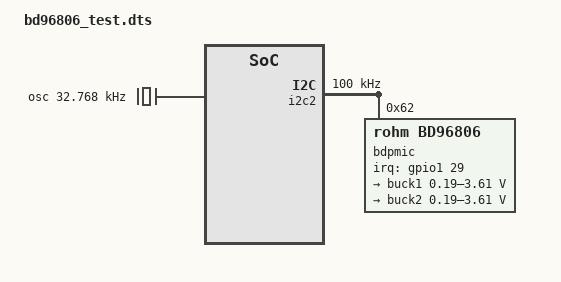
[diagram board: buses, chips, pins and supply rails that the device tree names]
/dts-v1/;
/plugin/;

/{ /* this is our device tree overlay root node */

	compatible = "ti,beaglebone", "ti,beaglebone-black";
	part-number = "BBB-I2C1"; // you can choose any name here but it should be memorable
 	version = "00A0";

/*
	fragment@0 {
		target = <&am33xx_pinmux>; // this is a link to an already defined node in the device tree, so that node is overlayed with our modification

		__overlay__ {
					b[2:0] = 2 => mux mode 2 (i2c1 p17/p18,SCL/SDA)
					b[3] = 0 => pullup/pulldown enabled
					b[4] = 1 => pull-up, not pull down
					b[5] = 1 => receiver active
					b[6] = 1 => slew control slow
			i2c1_pins: pinmux_i2c1_pins {
				pinctrl-single,pins = <
          			0x158 0x28 0x2 /* (INPUT_EN) MODE2 spi0_d1.i2c1_sda 
          			0x15C 0x28 0x2 /* spi0_cs0.i2c1_sdl 
        			>;
			};
		};
	};
*/
	fragment@1 {
		target-path = "/";
		__overlay__ {
			/* external oscillator */
			osc: oscillator {
				compatible = "fixed-clock";
				#clock-cells = <1>;
				clock-frequency  = <32768>;
				clock-output-names = "osc";
			};
		};
	};

	fragment@2 {
		target = <&i2c2>;

		__overlay__ {
			clock-frequency = <100000>;
			status = "okay";



			bdpmic: pmic@62 { /* the "test" defined as child of the i2c1 bus */
				reg = <0x62>;
/*				pinctrl-0 = <&i2c2_pins>; */
/*				pinctrl-names = "default"; */
				compatible = "rohm,bd96806";
				/* GPIO 1_29 - (connector 8, pin 26) for irq */
				interrupt-parent = <&gpio1>;
				/* interrupts = <29 8>; */
				interrupts = <29 8 /* 6 8 */>;
				interrupt-names = "intb" /*, "errb" */;
				/* 1500 ms cold reset */

				regulators {
					buck1 {
						regulator-name = "buck1";
						/* This is set only when PMIC is in STBY at SOC start-up */
						rohm,initial-voltage-microvolt = <500000>;
						/* 0.5V min INITIAL - 310 mV tune */
						regulator-min-microvolt = <190000>;
						/* 3.3V + 310mV tune */
						regulator-max-microvolt = <3610000>;

						regulator-ramp-delay = <10000>;
/*						regulator-ov-protection-microvolt = <1>; */
						regulator-ov-error-microvolt = <230000>;
/*						regulator-uv-protection-microvolt = <1>; */
						regulator-uv-error-microvolt = <230000>;
						regulator-temp-protection-kelvin = <1>;
						regulator-temp-warn-kelvin = <0>;
					};
					buck2 {
						regulator-name = "buck2";
						regulator-ramp-delay = <20000>;
						/* rohm,initial-voltage-microvolt = <600000>; */
						rohm,initial-voltage-microvolt = <3000000>;
						regulator-min-microvolt = <190000>;
						regulator-max-microvolt = <3610000>;
/*						regulator-ov-protection-microvolt = <1>; */
						regulator-ov-error-microvolt = <18000>;
						regulator-uv-error-microvolt = <18000>;
						regulator-temp-protection-kelvin = <1>;
						regulator-temp-warn-kelvin = <1>;
					};
				};
			};
		};
	};
}; /* root node end */
